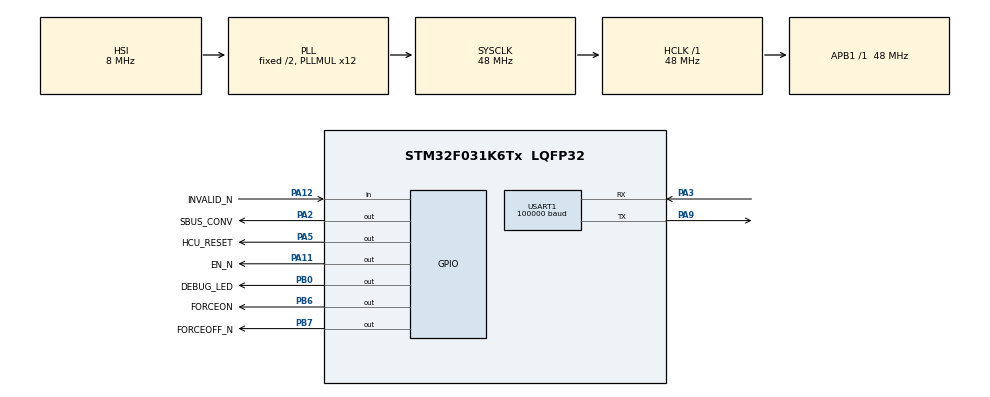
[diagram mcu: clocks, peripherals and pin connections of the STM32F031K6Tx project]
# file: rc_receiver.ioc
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Dma.Request0=USART1_RX
Dma.USART1_RX.0.Direction=DMA_PERIPH_TO_MEMORY
Dma.USART1_RX.0.Instance=DMA1_Channel3
Dma.USART1_RX.0.MemDataAlignment=DMA_MDATAALIGN_BYTE
Dma.USART1_RX.0.MemInc=DMA_MINC_ENABLE
Dma.USART1_RX.0.Mode=DMA_CIRCULAR
Dma.USART1_RX.0.PeriphDataAlignment=DMA_PDATAALIGN_BYTE
Dma.USART1_RX.0.PeriphInc=DMA_PINC_DISABLE
Dma.USART1_RX.0.Priority=DMA_PRIORITY_LOW
Mcu.Family=STM32F0
Mcu.Name=STM32F031K6Tx
Mcu.Package=LQFP32
NVIC.USART1_IRQn=true\:1\:0\:true\:false\:true\:true\:true\:true
PA11.GPIO_Label=EN_N
PA11.Signal=GPIO_Output
PA12.GPIO_Label=INVALID_N
PA12.Signal=GPIO_Input
PA13.Mode=Serial_Wire
PA13.Signal=SYS_SWDIO
PA14.Mode=Serial_Wire
PA14.Signal=SYS_SWCLK
PA2.GPIO_Label=SBUS_CONV
PA2.GPIO_Speed=GPIO_SPEED_FREQ_HIGH
PA2.Signal=GPIO_Output
PA3.Mode=Asynchronous
PA3.Signal=USART1_RX
PA5.GPIO_Label=HCU_RESET
PA5.Signal=GPIO_Output
PA9.Mode=Asynchronous
PA9.Signal=USART1_TX
PB0.GPIO_Label=DEBUG_LED
PB0.Signal=GPIO_Output
PB6.GPIO_Label=FORCEON
PB6.GPIO_Speed=GPIO_SPEED_FREQ_HIGH
PB6.Signal=GPIO_Output
PB7.GPIO_Label=FORCEOFF_N
PB7.GPIO_Speed=GPIO_SPEED_FREQ_HIGH
PB7.Signal=GPIO_Output
PF0-OSC_IN.Mode=HSE-External-Oscillator
PF0-OSC_IN.Signal=RCC_OSC_IN
PF1-OSC_OUT.Mode=HSE-External-Oscillator
PF1-OSC_OUT.Signal=RCC_OSC_OUT
ProjectManager.HeapSize=0x200
ProjectManager.StackSize=0x400
ProjectManager.TargetToolchain=STM32CubeIDE
RCC.AHBFreq_Value=48000000
RCC.APB1Freq_Value=48000000
RCC.APB1TimFreq_Value=48000000
RCC.HCLKFreq_Value=48000000
RCC.PLLMUL=RCC_PLL_MUL12
RCC.SYSCLKFreq_VALUE=48000000
RCC.SYSCLKSource=RCC_SYSCLKSOURCE_PLLCLK
USART1.BaudRate=100000
USART1.Mode=MODE_RX
USART1.OneBitSampling=UART_ONE_BIT_SAMPLE_DISABLE
USART1.OverSampling=UART_OVERSAMPLING_16
USART1.OverrunDisableParam=ADVFEATURE_OVERRUN_ENABLE
USART1.Parity=PARITY_EVEN
USART1.RxPinLevelInvertParam=ADVFEATURE_RXINV_ENABLE
USART1.StopBits=STOPBITS_2
USART1.VirtualMode-Asynchronous=VM_ASYNC
USART1.WordLength=WORDLENGTH_9B
VP_IWDG_VS_IWDG.Mode=IWDG_Activate
VP_TIM2_VS_ClockSourceINT.Mode=Internal
board=custom

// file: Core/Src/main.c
/* USER CODE BEGIN Header */
/**
 ******************************************************************************
 * @file           : main.c
 * @brief          : Main program body
 ******************************************************************************
 * @attention
 *
 * Copyright (c) 2023 STMicroelectronics.
 * All rights reserved.
 *
 * This software is licensed under terms that can be found in the LICENSE file
 * in the root directory of this software component.
 * If no LICENSE file comes with this software, it is provided AS-IS.
 *
 ******************************************************************************
 */
/* USER CODE END Header */
#include "main.h"

/* USER CODE BEGIN Includes */
#include "sbus_receive.h"
#include "software_uart.h"
/* USER CODE END Includes */

IWDG_HandleTypeDef hiwdg;

TIM_HandleTypeDef htim2;

UART_HandleTypeDef huart1;
DMA_HandleTypeDef hdma_usart1_rx;

/* USER CODE BEGIN PV */
uint8_t buffer[BUFFER_LENGTH * 2];
/* USER CODE END PV */

void SystemClock_Config(void);
static void MX_GPIO_Init(void);
static void MX_DMA_Init(void);
static void MX_USART1_UART_Init(void);
static void MX_TIM2_Init(void);
static void MX_IWDG_Init(void);

int main(void)
{

  /* MCU Configuration--------------------------------------------------------*/

  /* Reset of all peripherals, Initializes the Flash interface and the Systick. */
  HAL_Init();

  /* Configure the system clock */
  SystemClock_Config();

  /* Initialize all configured peripherals */
  MX_GPIO_Init();
  MX_DMA_Init();
  MX_USART1_UART_Init();
  MX_TIM2_Init();
  MX_IWDG_Init();
  /* USER CODE BEGIN 2 */

  InitializeHw();

  /* USER CODE END 2 */

  /* Infinite loop */
  while (1)
  {

  }
}

void SystemClock_Config(void)
{
  RCC_OscInitTypeDef RCC_OscInitStruct = {0};
  RCC_ClkInitTypeDef RCC_ClkInitStruct = {0};
  RCC_PeriphCLKInitTypeDef PeriphClkInit = {0};

  /** Initializes the RCC Oscillators according to the specified parameters
  * in the RCC_OscInitTypeDef structure.
  */
  RCC_OscInitStruct.OscillatorType = RCC_OSCILLATORTYPE_HSI|RCC_OSCILLATORTYPE_LSI;
  RCC_OscInitStruct.HSIState = RCC_HSI_ON;
  RCC_OscInitStruct.HSICalibrationValue = RCC_HSICALIBRATION_DEFAULT;
  RCC_OscInitStruct.LSIState = RCC_LSI_ON;
  RCC_OscInitStruct.PLL.PLLState = RCC_PLL_ON;
  RCC_OscInitStruct.PLL.PLLSource = RCC_PLLSOURCE_HSI;
  RCC_OscInitStruct.PLL.PLLMUL = RCC_PLL_MUL12;
  RCC_OscInitStruct.PLL.PREDIV = RCC_PREDIV_DIV1;
  if (HAL_RCC_OscConfig(&RCC_OscInitStruct) != HAL_OK)
  {
    Error_Handler();
  }

  /** Initializes the CPU, AHB and APB buses clocks
  */
  RCC_ClkInitStruct.ClockType = RCC_CLOCKTYPE_HCLK|RCC_CLOCKTYPE_SYSCLK
                              |RCC_CLOCKTYPE_PCLK1;
  RCC_ClkInitStruct.SYSCLKSource = RCC_SYSCLKSOURCE_PLLCLK;
  RCC_ClkInitStruct.AHBCLKDivider = RCC_SYSCLK_DIV1;
  RCC_ClkInitStruct.APB1CLKDivider = RCC_HCLK_DIV1;

  if (HAL_RCC_ClockConfig(&RCC_ClkInitStruct, FLASH_LATENCY_1) != HAL_OK)
  {
    Error_Handler();
  }
  PeriphClkInit.PeriphClockSelection = RCC_PERIPHCLK_USART1;
  PeriphClkInit.Usart1ClockSelection = RCC_USART1CLKSOURCE_PCLK1;
  if (HAL_RCCEx_PeriphCLKConfig(&PeriphClkInit) != HAL_OK)
  {
    Error_Handler();
  }
}

static void MX_IWDG_Init(void)
{

  hiwdg.Instance = IWDG;
  hiwdg.Init.Prescaler = IWDG_PRESCALER_4;
  hiwdg.Init.Window = 4095;
  hiwdg.Init.Reload = 4095;
  if (HAL_IWDG_Init(&hiwdg) != HAL_OK)
  {
    Error_Handler();
  }

}

static void MX_TIM2_Init(void)
{

  TIM_ClockConfigTypeDef sClockSourceConfig = {0};
  TIM_MasterConfigTypeDef sMasterConfig = {0};

  htim2.Instance = TIM2;
  htim2.Init.Prescaler = 0;
  htim2.Init.CounterMode = TIM_COUNTERMODE_UP;
  htim2.Init.Period = 4294967295;
  htim2.Init.ClockDivision = TIM_CLOCKDIVISION_DIV1;
  htim2.Init.AutoReloadPreload = TIM_AUTORELOAD_PRELOAD_DISABLE;
  if (HAL_TIM_Base_Init(&htim2) != HAL_OK)
  {
    Error_Handler();
  }
  sClockSourceConfig.ClockSource = TIM_CLOCKSOURCE_INTERNAL;
  if (HAL_TIM_ConfigClockSource(&htim2, &sClockSourceConfig) != HAL_OK)
  {
    Error_Handler();
  }
  sMasterConfig.MasterOutputTrigger = TIM_TRGO_RESET;
  sMasterConfig.MasterSlaveMode = TIM_MASTERSLAVEMODE_DISABLE;
  if (HAL_TIMEx_MasterConfigSynchronization(&htim2, &sMasterConfig) != HAL_OK)
  {
    Error_Handler();
  }

}

static void MX_USART1_UART_Init(void)
{

  huart1.Instance = USART1;
  huart1.Init.BaudRate = 100000;
  huart1.Init.WordLength = UART_WORDLENGTH_9B;
  huart1.Init.StopBits = UART_STOPBITS_2;
  huart1.Init.Parity = UART_PARITY_EVEN;
  huart1.Init.Mode = UART_MODE_RX;
  huart1.Init.HwFlowCtl = UART_HWCONTROL_NONE;
  huart1.Init.OverSampling = UART_OVERSAMPLING_16;
  huart1.Init.OneBitSampling = UART_ONE_BIT_SAMPLE_DISABLE;
  huart1.AdvancedInit.AdvFeatureInit = UART_ADVFEATURE_RXINVERT_INIT;
  huart1.AdvancedInit.RxPinLevelInvert = UART_ADVFEATURE_RXINV_ENABLE;
  if (HAL_UART_Init(&huart1) != HAL_OK)
  {
    Error_Handler();
  }

}

static void MX_DMA_Init(void)
{

  /* DMA controller clock enable */
  __HAL_RCC_DMA1_CLK_ENABLE();

}

static void MX_GPIO_Init(void)
{
  GPIO_InitTypeDef GPIO_InitStruct = {0};

  /* GPIO Ports Clock Enable */
  __HAL_RCC_GPIOF_CLK_ENABLE();
  __HAL_RCC_GPIOA_CLK_ENABLE();
  __HAL_RCC_GPIOB_CLK_ENABLE();

  /*Configure GPIO pin Output Level */
  HAL_GPIO_WritePin(GPIOA, SBUS_CONV_Pin|HCU_RESET_Pin|EN_N_Pin, GPIO_PIN_RESET);

  /*Configure GPIO pin Output Level */
  HAL_GPIO_WritePin(GPIOB, DEBUG_LED_Pin|FORCEON_Pin|FORCEOFF_N_Pin, GPIO_PIN_RESET);

  /*Configure GPIO pin : SBUS_CONV_Pin */
  GPIO_InitStruct.Pin = SBUS_CONV_Pin;
  GPIO_InitStruct.Mode = GPIO_MODE_OUTPUT_PP;
  GPIO_InitStruct.Pull = GPIO_NOPULL;
  GPIO_InitStruct.Speed = GPIO_SPEED_FREQ_HIGH;
  HAL_GPIO_Init(SBUS_CONV_GPIO_Port, &GPIO_InitStruct);

  /*Configure GPIO pins : HCU_RESET_Pin EN_N_Pin */
  GPIO_InitStruct.Pin = HCU_RESET_Pin|EN_N_Pin;
  GPIO_InitStruct.Mode = GPIO_MODE_OUTPUT_PP;
  GPIO_InitStruct.Pull = GPIO_NOPULL;
  GPIO_InitStruct.Speed = GPIO_SPEED_FREQ_LOW;
  HAL_GPIO_Init(GPIOA, &GPIO_InitStruct);

  /*Configure GPIO pin : DEBUG_LED_Pin */
  GPIO_InitStruct.Pin = DEBUG_LED_Pin;
  GPIO_InitStruct.Mode = GPIO_MODE_OUTPUT_PP;
  GPIO_InitStruct.Pull = GPIO_NOPULL;
  GPIO_InitStruct.Speed = GPIO_SPEED_FREQ_LOW;
  HAL_GPIO_Init(DEBUG_LED_GPIO_Port, &GPIO_InitStruct);

  /*Configure GPIO pin : INVALID_N_Pin */
  GPIO_InitStruct.Pin = INVALID_N_Pin;
  GPIO_InitStruct.Mode = GPIO_MODE_INPUT;
  GPIO_InitStruct.Pull = GPIO_NOPULL;
  HAL_GPIO_Init(INVALID_N_GPIO_Port, &GPIO_InitStruct);

  /*Configure GPIO pins : FORCEON_Pin FORCEOFF_N_Pin */
  GPIO_InitStruct.Pin = FORCEON_Pin|FORCEOFF_N_Pin;
  GPIO_InitStruct.Mode = GPIO_MODE_OUTPUT_PP;
  GPIO_InitStruct.Pull = GPIO_NOPULL;
  GPIO_InitStruct.Speed = GPIO_SPEED_FREQ_HIGH;
  HAL_GPIO_Init(GPIOB, &GPIO_InitStruct);

}

void Error_Handler(void)
{
  /* USER CODE BEGIN Error_Handler_Debug */
  /* User can add his own implementation to report the HAL error return state */
  __disable_irq();
  NVIC_SystemReset();
  while (1)
  {
  }
  /* USER CODE END Error_Handler_Debug */
}
